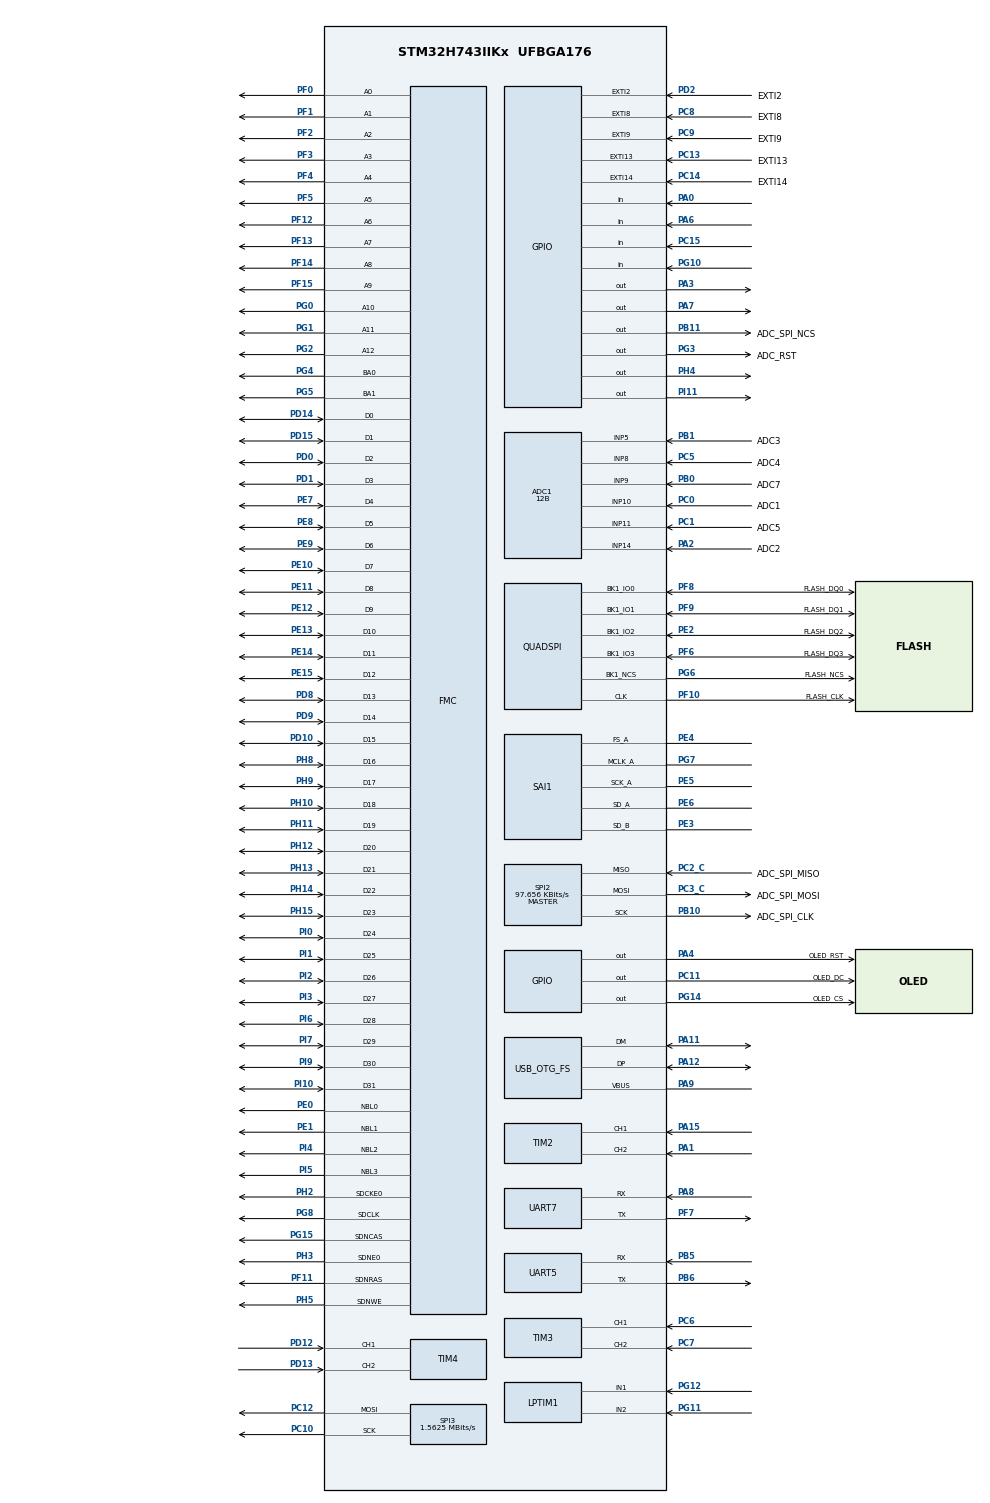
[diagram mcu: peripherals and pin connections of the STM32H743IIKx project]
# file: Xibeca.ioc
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Dma.SPI3_TX.2.MemInc=DMA_MINC_ENABLE
SH.FMC_A0.0=FMC_A0,13b-sda1
PG8.Signal=FMC_SDCLK
PG0.Signal=FMC_A10
RCC.PLLFRACN=0
PC3_C.Mode=Full_Duplex_Master
SAI1.Instance-SAI_A_MasterWithClock=SAI$Index_Block_A
PA15\ (JTDI).Signal=S_TIM2_CH1
SH.ADCx_INP5.0=ADC1_INP5,IN5-Single-Ended
SH.FMC_D5_DA5.0=FMC_D5,sd-32b-d1
SH.FMC_D9_DA9.0=FMC_D9,sd-32b-d1
USB_DEVICE.PID_AUDIO_FS=0xDADA
SH.FMC_D25.0=FMC_D25,sd-32b-d1
SAI1.FSDefinition-SAI_B_SyncSlave=SAI_FS_CHANNEL_IDENTIFICATION
PF7.Signal=UART7_TX
SH.FMC_SDNWE.0=FMC_SDNWE,13b-sda1
PH9.Signal=FMC_D17
SH.FMC_D11_DA11.0=FMC_D11,sd-32b-d1
Dma.SPI3_TX.2.PeriphDataAlignment=DMA_PDATAALIGN_BYTE
PB6.Signal=UART5_TX
PC7.Signal=S_TIM3_CH2
PD0.Signal=FMC_D2_DA2
SAI1.AudioMode-SAI_A_MasterWithClock=SAI_MODEMASTER_RX
PD8.Signal=FMC_D13_DA13
PE1.Signal=FMC_NBL1
QUADSPI.FlashSize=22
NVIC.EXTI15_10_IRQn=true\:5\:0\:false\:false\:true\:true\:true\:true
Dma.ADC1.3.RequestNumber=1
ADC1.OffsetSignedSaturation-3\#ChannelRegularConversion=DISABLE
USB_DEVICE.MANUFACTURER_STRING-AUDIO_FS=Rebel Technology
PC2_C.GPIO_Speed=GPIO_SPEED_FREQ_VERY_HIGH
RCC.SAI1CLockSelection=RCC_SAI1CLKSOURCE_PLL3
PE9.Signal=FMC_D6_DA6
Dma.SAI1_A.0.Polarity=HAL_DMAMUX_REQ_GEN_RISING
Dma.ADC1.3.Mode=DMA_CIRCULAR
SH.FMC_A2.0=FMC_A2,13b-sda1
PB1.GPIO_Label=ADC3
PA8.Signal=UART7_RX
SH.FMC_D1_DA1.0=FMC_D1,sd-32b-d1
Dma.SPI3_TX.2.Direction=DMA_MEMORY_TO_PERIPH
VP_FREERTOS_VS_CMSIS_V1.Mode=CMSIS_V1
PA0.Signal=GPIO_Input
Mcu.Package=UFBGA176
SAI1.AudioFrequency-SAI_A_MasterWithClock=SAI_AUDIO_FREQUENCY_48K
PB1.Signal=ADCx_INP5
PC10.Stacked=true
SAI1.SlotActive-SAI_B_SyncSlave=0x0000FFFF
SPI2.Mode=SPI_MODE_MASTER
ADC1.OversamplingMode=DISABLE
RCC.PLL3FRACN=0
SPI3.Mode=SPI_MODE_MASTER
PD12.Signal=S_TIM4_CH1
SAI1.FSPolarity-SAI_B_SyncSlave=SAI_FS_ACTIVE_HIGH
PC3_C.GPIO_Speed=GPIO_SPEED_FREQ_VERY_HIGH
PC3_C.GPIO_Label=ADC_SPI_MOSI
SH.FMC_D27.0=FMC_D27,sd-32b-d1
Dma.SAI1_A.0.SyncSignalID=NONE
NVIC.EXTI2_IRQn=true\:5\:0\:false\:false\:true\:true\:true\:true
SH.S_TIM4_CH1.0=TIM4_CH1,Encoder_Interface
PF10.Mode=Single Bank 1
PA4.GPIO_Label=OLED_RST
ADC1.EOCSelection=ADC_EOC_SEQ_CONV
PD15.Signal=FMC_D1_DA1
PG12.Signal=LPTIM1_IN1
SAI1.NoDivider-SAI_A_MasterWithClock=SAI_MASTERDIVIDER_ENABLE
USB_DEVICE.VID-AUDIO_FS=0x1209
SH.FMC_A4.0=FMC_A4,13b-sda1
FREERTOS.Tasks01=defaultTask,0,1024,StartDefaultTask,Default,NULL,Dynamic,NULL,NULL
PH13.Signal=FMC_D21
USB_DEVICE.VirtualMode-AUDIO_FS=Audio
Dma.SAI1_B.1.MemInc=DMA_MINC_ENABLE
SAI1.MClockEnable-SAI_A_MasterWithClock=SAI_MASTERCLOCK_ENABLE
PG5.Signal=FMC_A15_BA1
ADC1.OffsetNumber-0\#ChannelRegularConversion=ADC_OFFSET_NONE
PC13.Signal=GPXTI13
SH.FMC_D10_DA10.0=FMC_D10,sd-32b-d1
FREERTOS.INCLUDE_vTaskDelayUntil=1
Dma.ADC1.3.Priority=DMA_PRIORITY_LOW
SAI1.ErrorAudioFreq-SAI_A_MasterWithClock=-0.01 %
SH.FMC_D16.0=FMC_D16,sd-32b-d1
SH.ADCx_INP9.0=ADC1_INP9,IN9-Single-Ended
RCC.PWR_Regulator_Voltage_Scale=PWR_REGULATOR_VOLTAGE_SCALE0
PF8.GPIO_Label=FLASH_DQ0
PD10.Signal=FMC_D15_DA15
SH.FMC_D29.0=FMC_D29,sd-32b-d1
SAI1.VirtualMode-SAI_A_MasterWithClock=VM_MASTER
PI7.Signal=FMC_D29
PC2_C.GPIO_Label=ADC_SPI_MISO
SH.FMC_A6.0=FMC_A6,13b-sda1
PE14.Signal=FMC_D11_DA11
PE6.Mode=SAI_A_MasterWithClock
SAI1.SlotNumber-SAI_B_SyncSlave=8
Dma.ADC1.3.SyncSignalID=NONE
PI2.Signal=FMC_D26
Dma.ADC1.3.Polarity=HAL_DMAMUX_REQ_GEN_RISING
Dma.SAI1_A.0.SyncRequestNumber=1
FREERTOS.configUSE_MUTEXES=0
QUADSPI.FifoThreshold=4
PF13.Signal=FMC_A7
SH.SharedStack_PC8.0=SDMMC1_D0
SH.SharedStack_PC8.1=GPIO_EXTI8
SH.FMC_NBL2.0=FMC_NBL2,Sd4ByteEnable1
SH.FMC_D18.0=FMC_D18,sd-32b-d1
Dma.SPI3_TX.2.SyncEnable=DISABLE
ADC1.master=1
PC14-OSC32_IN\ (OSC32_IN).GPIO_Label=EXTI14
ProjectManager.HeapSize=0x200
NVIC.PriorityGroup=NVIC_PRIORITYGROUP_4
ADC1.ConversionDataManagement=ADC_CONVERSIONDATA_DMA_CIRCULAR
PE3.Signal=SAI1_SD_B
PF4.Signal=FMC_A4
PD2.Signal=SharedStack_PD2
Mcu.Family=STM32H7
SH.SharedStack_PC12.1=SPI3_MOSI,TX_Only_Simplex_Unidirect_Master
SH.SharedStack_PC12.0=SDMMC1_CK
USB_DEVICE.CLASS_NAME_FS=AUDIO
ADC1.OffsetSignedSaturation-1\#ChannelRegularConversion=DISABLE
SH.FMC_A8.0=FMC_A8,13b-sda1
PH14.Signal=FMC_D22
PH10.Signal=FMC_D18
ADC1.Overrun=ADC_OVR_DATA_OVERWRITTEN
ADC1.ContinuousConvMode=ENABLE
SH.FMC_D14_DA14.0=FMC_D14,sd-32b-d1
PH0-OSC_IN\ (PH0).Signal=RCC_OSC_IN
PG2.Signal=FMC_A12
SAI1.FrameLength-SAI_B_SyncSlave=256
TIM4.EncoderMode=TIM_ENCODERMODE_TI12
SAI1.FSDefinition-SAI_A_MasterWithClock=SAI_FS_CHANNEL_IDENTIFICATION
PE2.GPIO_Speed=GPIO_SPEED_FREQ_VERY_HIGH
PA11.Mode=Device_Only
PF9.GPIO_Speed=GPIO_SPEED_FREQ_VERY_HIGH
RCC.PLL2FRACN=6144
SAI1.OutputDrive-SAI_B_SyncSlave=SAI_OUTPUTDRIVE_ENABLE
SH.FMC_A14_BA0.0=FMC_BA0,FourSdramBanks1
SH.FMC_A11.0=FMC_A11,13b-sda1
Dma.SPI3_TX.2.Mode=DMA_NORMAL
PG15.Signal=FMC_SDNCAS
PG11.Signal=LPTIM1_IN2
PD13.Signal=S_TIM4_CH2
Dma.SPI3_TX.2.SignalID=NONE
SAI1.VirtualMode-SAI_B_SyncSlave=VM_SLAVE
Dma.SAI1_B.1.SyncPolarity=HAL_DMAMUX_SYNC_NO_EVENT
ADC1.Channel-3\#ChannelRegularConversion=ADC_CHANNEL_8
SAI1.ActiveFrameLength-SAI_B_SyncSlave=128
Dma.ADC1.3.SyncPolarity=HAL_DMAMUX_SYNC_NO_EVENT
ADC1.Resolution=ADC_RESOLUTION_12B
SH.FMC_NBL1.0=FMC_NBL1,Sd4ByteEnable1
Dma.SAI1_B.1.Instance=DMA1_Stream1
Dma.SAI1_B.1.FIFOMode=DMA_FIFOMODE_DISABLE
FREERTOS.configUSE_PREEMPTION=0
ADC1.Channel-0\#ChannelRegularConversion=ADC_CHANNEL_10
PH1-OSC_OUT\ (PH1).Mode=HSE-External-Oscillator
RCC.HSE_VALUE=8000000
SH.SharedStack_PC10.1=SPI3_SCK,TX_Only_Simplex_Unidirect_Master
PA4.GPIO_Speed=GPIO_SPEED_FREQ_MEDIUM
SH.SharedStack_PC10.0=SDMMC1_D2
PF9.Mode=Single Bank 1
PF11.Signal=FMC_SDNRAS
PC11.GPIO_Label=OLED_DC
PB5.Mode=Asynchronous
PB7.Signal=I2C1_SDA
SH.S_TIM3_CH1.0=TIM3_CH1,Encoder_Interface
SAI1.OutputDrive-SAI_A_MasterWithClock=SAI_OUTPUTDRIVE_ENABLE
USB_DEVICE.PRODUCT_STRING_AUDIO_FS=OWL-XIBECA
PA6.Signal=GPIO_Input
Dma.SAI1_A.0.MemDataAlignment=DMA_MDATAALIGN_WORD
NVIC.OTG_FS_IRQn=true\:5\:0\:false\:false\:true\:true\:true\:true
SAI1.FSOffset-SAI_A_MasterWithClock=SAI_FS_BEFOREFIRSTBIT
PF8.Signal=QUADSPI_BK1_IO0
NVIC.SPI3_IRQn=true\:5\:0\:false\:false\:true\:true\:false\:true
Dma.Request2=SPI3_TX
Dma.Request1=SAI1_B
Dma.SAI1_B.1.PeriphInc=DMA_PINC_DISABLE
Dma.Request3=ADC1
FREERTOS.configUSE_TICK_HOOK=0
NVIC.DMA1_Stream0_IRQn=true\:5\:0\:false\:false\:true\:true\:false\:true
PC5.Signal=ADCx_INP8
PH2.Mode=SdramChipSelect1_1
PE7.Signal=FMC_D4_DA4
Dma.Request0=SAI1_A
Dma.SAI1_B.1.Priority=DMA_PRIORITY_VERY_HIGH
PE2.GPIO_Label=FLASH_DQ2
PA3.Signal=GPIO_Output
SAI1.VirtualSlotActive-SAI_A_MasterWithClock=SAI_SLOTACTIVE_ALL
SH.FMC_D20.0=FMC_D20,sd-32b-d1
SH.S_TIM2_CH1.0=TIM2_CH1,Encoder_Interface
Dma.SAI1_B.1.Mode=DMA_CIRCULAR
PG7.Signal=SAI1_MCLK_A
PC9.GPIO_Label=EXTI9
Dma.SAI1_B.1.RequestNumber=1
Dma.SPI3_TX.2.Polarity=HAL_DMAMUX_REQ_GEN_RISING
Dma.SAI1_A.0.Direction=DMA_PERIPH_TO_MEMORY
PC11.Signal=GPIO_Output
Dma.SAI1_A.0.SignalID=NONE
SPI2.NSSPMode=SPI_NSS_PULSE_DISABLE
PC8.Signal=SharedStack_PC8
PF10.GPIO_Speed=GPIO_SPEED_FREQ_VERY_HIGH
SH.ADCx_INP14.0=ADC1_INP14,IN14-Single-Ended
SH.FMC_D31.0=FMC_D31,sd-32b-d1
PD9.Signal=FMC_D14_DA14
PC12.Stacked=true
PH1-OSC_OUT\ (PH1).Signal=RCC_OSC_OUT
FREERTOS.configUSE_IDLE_HOOK=0
SAI1.RealAudioFreq-SAI_A_MasterWithClock=47.991 KHz
PA9.Mode=Activate_VBUS
SH.SharedStack_PD2.0=SDMMC1_CMD
PF6.Signal=QUADSPI_BK1_IO3
SH.SharedStack_PD2.1=GPIO_EXTI2
PC15-OSC32_OUT\ (OSC32_OUT).Signal=GPIO_Input
PB10.GPIO_Label=ADC_SPI_CLK
Dma.SAI1_A.0.Mode=DMA_CIRCULAR
SH.FMC_D13_DA13.0=FMC_D13,sd-32b-d1
PH8.Signal=FMC_D16
Dma.ADC1.3.SyncRequestNumber=1
RCC.USBFreq_Value=48000000
PF9.GPIO_Label=FLASH_DQ1
Dma.SAI1_B.1.SyncEnable=DISABLE
PA1.Signal=S_TIM2_CH2
Dma.ADC1.3.Direction=DMA_PERIPH_TO_MEMORY
board=custom
PG12.Mode=Encoder_mode_occur1
PI9.Signal=FMC_D30
SH.FMC_D22.0=FMC_D22,sd-32b-d1
PI4.Signal=FMC_NBL2
PE5.Mode=SAI_A_MasterWithClock
RCC.ADCFreq_Value=25000000
PC1.GPIO_Label=ADC5
SH.FMC_D12_DA12.0=FMC_D12,sd-32b-d1
SAI1.SlotNumber-SAI_A_MasterWithClock=8
PF1.Signal=FMC_A1
VP_USB_DEVICE_VS_USB_DEVICE_AUDIO_FS.Mode=AUDIO_FS
ADC1.NbrOfConversion=4
ADC1.OffsetNumber-2\#ChannelRegularConversion=ADC_OFFSET_NONE
PE0.Signal=FMC_NBL0
Dma.SAI1_B.1.SyncSignalID=NONE
PE12.Signal=FMC_D9_DA9
RCC.SYSCLKFreq_VALUE=480000000
ADC1.Rank-3\#ChannelRegularConversion=4
ADC1.SamplingTime-3\#ChannelRegularConversion=ADC_SAMPLETIME_387CYCLES_5
NVIC.EXTI9_5_IRQn=true\:5\:0\:false\:false\:true\:true\:true\:true
PH3.Signal=FMC_SDNE0
PC3_C.Signal=SPI2_MOSI
PE5.GPIO_Speed=GPIO_SPEED_FREQ_VERY_HIGH
NVIC.DMA1_Stream3_IRQn=true\:5\:0\:false\:false\:true\:true\:false\:true
PG14.GPIO_Speed=GPIO_SPEED_FREQ_MEDIUM
PC12.GPIO_Speed=GPIO_SPEED_FREQ_HIGH
Dma.SAI1_A.0.SyncEnable=DISABLE
SAI1.SlotActive-SAI_A_MasterWithClock=0x0000FFFF
SH.FMC_D7_DA7.0=FMC_D7,sd-32b-d1
SH.FMC_D24.0=FMC_D24,sd-32b-d1
SPI3.Direction=SPI_DIRECTION_2LINES_TXONLY
SPI3.VirtualType=VM_MASTER
PH12.Signal=FMC_D20
QUADSPI.ClockPrescaler=9
SPI2.VirtualType=VM_MASTER
PB10.Mode=Full_Duplex_Master
SH.ADCx_INP10.0=ADC1_INP10,IN10-Single-Ended
PG4.Signal=FMC_A14_BA0
NVIC.DMA1_Stream2_IRQn=true\:5\:0\:false\:false\:true\:true\:false\:true
PC12.Signal=SharedStack_PC12
PG6.GPIO_Label=FLASH_NCS
PG6.Mode=Single Bank 1
PF6.GPIO_Label=FLASH_DQ3
RCC.SYSCLKSource=RCC_SYSCLKSOURCE_PLLCLK
SH.FMC_A15_BA1.0=FMC_BA1,FourSdramBanks1
RCC.SPI123CLockSelection=RCC_SPI123CLKSOURCE_PLL2
Dma.ADC1.3.MemInc=DMA_MINC_ENABLE
PA14\ (JTCK/SWCLK).Signal=DEBUG_JTCK-SWCLK
PH5.Signal=FMC_SDNWE
Dma.SPI3_TX.2.SyncRequestNumber=1
PE2.Mode=Single Bank 1
ADC1.Channel-2\#ChannelRegularConversion=ADC_CHANNEL_5
PB6.Mode=Asynchronous
PE5.Signal=SAI1_SCK_A
PF10.GPIO_Label=FLASH_CLK
Dma.SAI1_B.1.PeriphDataAlignment=DMA_PDATAALIGN_WORD
RCC.DIVM3=7
RCC.DIVM2=1
RCC.DIVM1=1
Dma.ADC1.3.Instance=DMA1_Stream3
SH.FMC_D26.0=FMC_D26,sd-32b-d1
PI6.Signal=FMC_D28
PI3.Signal=FMC_D27
SPI2.CalculateBaudRate=97.656 KBits/s
PC11.GPIO_Speed=GPIO_SPEED_FREQ_MEDIUM
SH.S_TIM4_CH2.0=TIM4_CH2,Encoder_Interface
PE2.Signal=QUADSPI_BK1_IO2
PF8.Mode=Single Bank 1
PA14\ (JTCK/SWCLK).Mode=Trace_Asynchronous_SW
PF3.Signal=FMC_A3
NVIC.SAI1_IRQn=true\:5\:0\:false\:false\:true\:true\:true\:true
PE10.Signal=FMC_D7_DA7
ADC1.SamplingTime-0\#ChannelRegularConversion=ADC_SAMPLETIME_387CYCLES_5
SH.FMC_A1.0=FMC_A1,13b-sda1
PH2.Signal=FMC_SDCKE0
SH.FMC_SDCLK.0=FMC_SDCLK,13b-sda1
RCC.APB4Freq_Value=120000000
PF14.Signal=FMC_A8
SAI1.FrameLength-SAI_A_MasterWithClock=256
PI11.Signal=GPIO_Output
PH0-OSC_IN\ (PH0).Mode=HSE-External-Oscillator
PE6.GPIO_Speed=GPIO_SPEED_FREQ_VERY_HIGH
SH.FMC_D3_DA3.0=FMC_D3,sd-32b-d1
PG6.GPIO_Speed=GPIO_SPEED_FREQ_VERY_HIGH
Dma.SAI1_B.1.EventEnable=DISABLE
NVIC.QUADSPI_IRQn=true\:5\:0\:false\:false\:true\:true\:true\:true
PH15.Signal=FMC_D23
SAI1.DataSize-SAI_B_SyncSlave=SAI_DATASIZE_24
RCC.DIVQ1=5
ADC1.Rank-0\#ChannelRegularConversion=1
SH.FMC_D28.0=FMC_D28,sd-32b-d1
FREERTOS.configCHECK_FOR_STACK_OVERFLOW=2
Dma.SPI3_TX.2.EventEnable=DISABLE
PC6.Signal=S_TIM3_CH1
PB11.GPIO_Label=ADC_SPI_NCS
PD1.Signal=FMC_D3_DA3
RCC.DIVP2=6
TIM4.IC2Filter=4
PC0.Signal=ADCx_INP10
PC9.Stacked=true
PG10.Signal=GPIO_Input
SH.FMC_A3.0=FMC_A3,13b-sda1
Dma.SAI1_A.0.RequestNumber=1
SH.FMC_D15_DA15.0=FMC_D15,sd-32b-d1
PA9.Signal=USB_OTG_FS_VBUS
RCC.DIVN3=172
RCC.DIVN2=18
RCC.DIVN1=120
PC2_C.Mode=Full_Duplex_Master
SH.SharedStack_PC9.0=SDMMC1_D1
SH.SharedStack_PC9.1=GPIO_EXTI9
SH.FMC_D17.0=FMC_D17,sd-32b-d1
ADC1.OffsetSignedSaturation-0\#ChannelRegularConversion=DISABLE
SH.ADCx_INP8.0=ADC1_INP8,IN8-Single-Ended
PB10.Signal=SPI2_SCK
RCC.USBCLockSelection=RCC_USBCLKSOURCE_HSI48
Dma.SAI1_A.0.PeriphInc=DMA_PINC_DISABLE
PE15.Signal=FMC_D12_DA12
PE8.Signal=FMC_D5_DA5
PI1.Signal=FMC_D25
SH.FMC_SDNCAS.0=FMC_SDNCAS,13b-sda1
PG14.GPIO_Label=OLED_CS
Dma.SAI1_B.1.MemDataAlignment=DMA_MDATAALIGN_WORD
PA4.Signal=GPIO_Output
ADC1.SamplingTime-1\#ChannelRegularConversion=ADC_SAMPLETIME_387CYCLES_5
PB5.Signal=UART5_RX
PE3.GPIO_Speed=GPIO_SPEED_FREQ_VERY_HIGH
ADC1.Rank-1\#ChannelRegularConversion=2
SH.FMC_A5.0=FMC_A5,13b-sda1
PG11.Mode=Encoder_mode_occur1
PA11.Signal=USB_OTG_FS_DM
Dma.SPI3_TX.2.PeriphInc=DMA_PINC_DISABLE
Dma.ADC1.3.SignalID=NONE
PF6.Mode=Single Bank 1
PF9.Signal=QUADSPI_BK1_IO1
PB3\ (JTDO/TRACESWO).Mode=Trace_Asynchronous_SW
Dma.ADC1.3.EventEnable=DISABLE
PA8.Mode=Asynchronous
SPI2.DataSize=SPI_DATASIZE_8BIT
SH.FMC_NBL3.0=FMC_NBL3,Sd4ByteEnable1
PG3.GPIO_Label=ADC_RST
PB0.Signal=ADCx_INP9
SAI1.SlotSize-SAI_B_SyncSlave=SAI_SLOTSIZE_32B
SH.FMC_D19.0=FMC_D19,sd-32b-d1
Dma.SAI1_A.0.FIFOMode=DMA_FIFOMODE_DISABLE
PC1.Signal=ADCx_INP11
Dma.SAI1_A.0.Instance=DMA1_Stream0
PD2.GPIO_Label=EXTI2
Dma.SAI1_A.0.PeriphDataAlignment=DMA_PDATAALIGN_WORD
PA13\ (JTMS/SWDIO).Signal=DEBUG_JTMS-SWDIO
PF6.GPIO_Speed=GPIO_SPEED_FREQ_VERY_HIGH
RCC.CortexFreq_Value=480000000
PG6.Signal=QUADSPI_BK1_NCS
PB10.GPIO_Speed=GPIO_SPEED_FREQ_VERY_HIGH
Dma.SPI3_TX.2.Instance=DMA1_Stream2
RCC.HPRE=RCC_HCLK_DIV2
SPI3.NSSPMode=SPI_NSS_PULSE_DISABLE
PC10.Signal=SharedStack_PC10
SH.FMC_NBL0.0=FMC_NBL0,Sd4ByteEnable1
PC0.GPIO_Label=ADC1
SH.FMC_D6_DA6.0=FMC_D6,sd-32b-d1
PB0.GPIO_Label=ADC7
PC10.GPIO_Speed=GPIO_SPEED_FREQ_HIGH
PC13.GPIO_Label=EXTI13
Dma.ADC1.3.PeriphDataAlignment=DMA_PDATAALIGN_HALFWORD
PB11.Signal=GPIO_Output
SAI1.ActiveFrameLength-SAI_A_MasterWithClock=128
Dma.SPI3_TX.2.SyncSignalID=NONE
ProjectManager.StackSize=0x400
PH3.Mode=SdramChipSelect1_1
NVIC.ADC_IRQn=true\:5\:0\:false\:false\:true\:true\:true\:true
SH.FMC_A7.0=FMC_A7,13b-sda1
PA12.Signal=USB_OTG_FS_DP
SPI2.CLKPolarity=SPI_POLARITY_HIGH
RCC.HCLKFreq_Value=240000000
Dma.ADC1.3.PeriphInc=DMA_PINC_DISABLE
PF12.Signal=FMC_A6
FREERTOS.configUSE_MALLOC_FAILED_HOOK=1
Dma.SAI1_A.0.SyncPolarity=HAL_DMAMUX_SYNC_NO_EVENT
PC2_C.Signal=SPI2_MISO
SH.FMC_A10.0=FMC_A10,13b-sda1
SPI2.BaudRatePrescaler=SPI_BAUDRATEPRESCALER_256
SPI3.DataSize=SPI_DATASIZE_8BIT
SH.FMC_D8_DA8.0=FMC_D8,sd-32b-d1
PC8.Stacked=true
SH.FMC_D2_DA2.0=FMC_D2,sd-32b-d1
ADC1.Rank-2\#ChannelRegularConversion=3
PE13.Signal=FMC_D10_DA10
PI5.Signal=FMC_NBL3
PE4.GPIO_Speed=GPIO_SPEED_FREQ_VERY_HIGH
PI0.Signal=FMC_D24
Dma.SAI1_A.0.EventEnable=DISABLE
PE4.Mode=SAI_A_MasterWithClock
Dma.SPI3_TX.2.Priority=DMA_PRIORITY_LOW
SH.FMC_SDNRAS.0=FMC_SDNRAS,13b-sda1
PE4.Signal=SAI1_FS_A
RCC.APB3Freq_Value=120000000
SAI1.VirtualSlotActive-SAI_B_SyncSlave=SAI_SLOTACTIVE_ALL
Dma.SPI3_TX.2.FIFOMode=DMA_FIFOMODE_DISABLE
SH.FMC_D0_DA0.0=FMC_D0,sd-32b-d1
RCC.D1PPRE=RCC_APB3_DIV2
PA2.GPIO_Label=ADC2
USB_OTG_FS.VirtualMode=Device_Only
SH.FMC_A9.0=FMC_A9,13b-sda1
ADC1.OffsetNumber-1\#ChannelRegularConversion=ADC_OFFSET_NONE
SH.FMC_D4_DA4.0=FMC_D4,sd-32b-d1
SPI2.CLKPhase=SPI_PHASE_2EDGE
TIM4.IC1Filter=4
PF5.Signal=FMC_A5
Dma.SAI1_B.1.SignalID=NONE
Dma.SPI3_TX.2.RequestNumber=1
SH.FMC_D30.0=FMC_D30,sd-32b-d1
SPI2.Direction=SPI_DIRECTION_2LINES
PF0.Signal=FMC_A0
PE3.Mode=SAI_B_SyncSlave
SH.FMC_A12.0=FMC_A12,13b-sda1
RCC.PLLSourceVirtual=RCC_PLLSOURCE_HSE
PA13\ (JTMS/SWDIO).Mode=Trace_Asynchronous_SW
Dma.SAI1_B.1.Polarity=HAL_DMAMUX_REQ_GEN_RISING
PH11.Signal=FMC_D19
USB_DEVICE.VirtualModeFS=Audio_FS
PG3.Signal=GPIO_Output
PG1.Signal=FMC_A11
SAI1.FSPolarity-SAI_A_MasterWithClock=SAI_FS_ACTIVE_HIGH
ADC1.OffsetNumber-3\#ChannelRegularConversion=ADC_OFFSET_NONE
RCC.D2PPRE2=RCC_APB2_DIV2
RCC.D2PPRE1=RCC_APB1_DIV2
PI10.Signal=FMC_D31
NVIC.DMA1_Stream1_IRQn=true\:5\:0\:false\:false\:true\:true\:false\:true
Dma.SAI1_A.0.MemInc=DMA_MINC_ENABLE
Dma.SPI3_TX.2.SyncPolarity=HAL_DMAMUX_SYNC_NO_EVENT
Dma.ADC1.3.FIFOMode=DMA_FIFOMODE_DISABLE
ADC1.SamplingTime-2\#ChannelRegularConversion=ADC_SAMPLETIME_387CYCLES_5
PD2.Stacked=true
Dma.ADC1.3.SyncEnable=DISABLE
PC8.GPIO_Label=EXTI8
SH.FMC_D21.0=FMC_D21,sd-32b-d1
PF7.Mode=Asynchronous
SH.S_TIM2_CH2.0=TIM2_CH2,Encoder_Interface
PH4.Signal=GPIO_Output
PB3\ (JTDO/TRACESWO).Signal=DEBUG_JTDO-SWO
ProjectManager.TargetToolchain=Other Toolchains (GPDSC)
SAI1.SlotSize-SAI_A_MasterWithClock=SAI_SLOTSIZE_32B
ADC1.OffsetSignedSaturation-2\#ChannelRegularConversion=DISABLE
ADC1.Channel-1\#ChannelRegularConversion=ADC_CHANNEL_14
SAI1.DataSize-SAI_A_MasterWithClock=SAI_DATASIZE_24
PF2.Signal=FMC_A2
PG7.Mode=SAI_A_MasterWithClock
PE11.Signal=FMC_D8_DA8
SAI1.AudioMode-SAI_B_SyncSlave=SAI_MODESLAVE_TX
Dma.SAI1_A.0.Priority=DMA_PRIORITY_VERY_HIGH
PG14.Signal=GPIO_Output
SH.S_TIM3_CH2.0=TIM3_CH2,Encoder_Interface
Dma.ADC1.3.MemDataAlignment=DMA_MDATAALIGN_HALFWORD
PG7.GPIO_Speed=GPIO_SPEED_FREQ_VERY_HIGH
RCC.APB2Freq_Value=120000000
SPI3.CalculateBaudRate=1.5625 MBits/s
PF10.Signal=QUADSPI_CLK
Dma.SPI3_TX.2.MemDataAlignment=DMA_MDATAALIGN_BYTE
SPI3.BaudRatePrescaler=SPI_BAUDRATEPRESCALER_16
PD13.GPIO_PuPd=GPIO_PULLUP
PF15.Signal=FMC_A9
PE6.Signal=SAI1_SD_A
Mcu.Name=STM32H743IIKx
PA2.Signal=ADCx_INP14
PD14.Signal=FMC_D0_DA0
PA12.Mode=Device_Only
Dma.SAI1_B.1.Direction=DMA_MEMORY_TO_PERIPH
PC14-OSC32_IN\ (OSC32_IN).Signal=GPXTI14
PC5.GPIO_Label=ADC4
SH.FMC_D23.0=FMC_D23,sd-32b-d1
SAI1.Instance-SAI_B_SyncSlave=SAI$Index_Block_B
SH.ADCx_INP11.0=ADC1_INP11,IN11-Single-Ended
ADC1.NbrOfConversionFlag=1
SAI1.FSOffset-SAI_B_SyncSlave=SAI_FS_BEFOREFIRSTBIT
PF8.GPIO_Speed=GPIO_SPEED_FREQ_VERY_HIGH
Dma.SAI1_B.1.SyncRequestNumber=1
RCC.D3PPRE=RCC_APB4_DIV2
PC9.Signal=SharedStack_PC9
NVIC.TIM4_IRQn=true\:5\:0\:false\:false\:true\:true\:true\:true
RCC.APB1Freq_Value=120000000
ADC1.ClockPrescaler=ADC_CLOCK_SYNC_PCLK_DIV4
SAI1.ClockStrobing-SAI_A_MasterWithClock=SAI_CLOCKSTROBING_RISINGEDGE
PD12.GPIO_PuPd=GPIO_PULLUP
PA7.Signal=GPIO_Output

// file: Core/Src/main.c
/* USER CODE BEGIN Header */
/**
  ******************************************************************************
  * @file           : main.c
  * @brief          : Main program body
  ******************************************************************************
  * @attention
  *
  * <h2><center>&copy; Copyright (c) 2021 STMicroelectronics.
  * All rights reserved.</center></h2>
  *
  * This software component is licensed by ST under Ultimate Liberty license
  * SLA0044, the "License"; You may not use this file except in compliance with
  * the License. You may obtain a copy of the License at:
  *                             www.st.com/SLA0044
  *
  ******************************************************************************
  */
/* USER CODE END Header */
#include "main.h"
#include "cmsis_os.h"
#include "usb_device.h"

/* USER CODE BEGIN Includes */
#include "device.h"
#include "errorhandlers.h"
/* USER CODE END Includes */

ADC_HandleTypeDef hadc1;
DMA_HandleTypeDef hdma_adc1;

LPTIM_HandleTypeDef hlptim1;

QSPI_HandleTypeDef hqspi;

SAI_HandleTypeDef hsai_BlockA1;
SAI_HandleTypeDef hsai_BlockB1;
DMA_HandleTypeDef hdma_sai1_a;
DMA_HandleTypeDef hdma_sai1_b;

SPI_HandleTypeDef hspi2;
SPI_HandleTypeDef hspi3;
DMA_HandleTypeDef hdma_spi3_tx;

TIM_HandleTypeDef htim2;
TIM_HandleTypeDef htim3;
TIM_HandleTypeDef htim4;

UART_HandleTypeDef huart5;
UART_HandleTypeDef huart7;

SDRAM_HandleTypeDef hsdram1;

osThreadId defaultTaskHandle;

void SystemClock_Config(void);
void PeriphCommonClock_Config(void);
static void MX_GPIO_Init(void);
static void MX_DMA_Init(void);
static void MX_QUADSPI_Init(void);
static void MX_FMC_Init(void);
static void MX_SAI1_Init(void);
static void MX_ADC1_Init(void);
static void MX_SPI2_Init(void);
static void MX_SPI3_Init(void);
static void MX_TIM2_Init(void);
static void MX_TIM3_Init(void);
static void MX_TIM4_Init(void);
static void MX_UART5_Init(void);
static void MX_UART7_Init(void);
static void MX_LPTIM1_Init(void);
void StartDefaultTask(void const * argument);

/* USER CODE BEGIN PFP */
void setup(void);
void loop(void);
void SDRAM_Initialization_Sequence(SDRAM_HandleTypeDef *hsdram);
void initialise_monitor_handles(void);
/* USER CODE END PFP */

int main(void)
{
  /* USER CODE BEGIN 1 */
#ifdef DEBUG
#warning "DEBUG uses printf and semihosting!"
  if(CoreDebug->DHCSR & 0x01)
    initialise_monitor_handles(); // remove when not semi-hosting
  printf("showtime\n");
#endif
#ifdef USE_ICACHE
  /* Enable I-Cache-------------------------------------------------------------*/
  /* After reset, you must invalidate each cache before enabling (SCB_EnableICache) it. */
  SCB_InvalidateICache();
  SCB_EnableICache();
#endif
#ifdef USE_DCACHE
  /* Enable D-Cache-------------------------------------------------------------*/
  /* Before enabling the data cache, you must invalidate the entire data cache (SCB_InvalidateDCache), because external memory might have changed from when the cache was disabled. */
  SCB_InvalidateDCache();
  SCB_EnableDCache();
#endif

  /* Enable D2 domain SRAM Clocks */
  /* presumably done in SystemInit by setting DATA_IN_D2_SRAM ? */
  /* should be started before libc_init_array and LoopCopyData in startup.s */
  /* __HAL_RCC_D2SRAM1_CLK_ENABLE(); */
  /* __HAL_RCC_D2SRAM2_CLK_ENABLE(); */
  /* __HAL_RCC_D2SRAM3_CLK_ENABLE(); */

  /* USER CODE END 1 */

  /* MCU Configuration--------------------------------------------------------*/

  /* Reset of all peripherals, Initializes the Flash interface and the Systick. */
  HAL_Init();

  /* Configure the system clock */
  SystemClock_Config();

/* Configure the peripherals common clocks */
  PeriphCommonClock_Config();

  /* Initialize all configured peripherals */
  MX_GPIO_Init();
  MX_DMA_Init();
  MX_QUADSPI_Init();
  MX_FMC_Init();
  MX_SAI1_Init();
  MX_ADC1_Init();
  MX_SPI2_Init();
  MX_SPI3_Init();
  MX_TIM2_Init();
  MX_TIM3_Init();
  MX_TIM4_Init();
  MX_UART5_Init();
  MX_UART7_Init();
  MX_LPTIM1_Init();
  /* USER CODE BEGIN 2 */

#ifdef USE_EXTERNAL_RAM
  SDRAM_Initialization_Sequence(&hsdram1);
#endif

  /* USER CODE END 2 */

  /* Create the thread(s) */
  /* definition and creation of defaultTask */
  osThreadDef(defaultTask, StartDefaultTask, osPriorityNormal, 0, 1024);
  defaultTaskHandle = osThreadCreate(osThread(defaultTask), NULL);

  /* Start scheduler */
  osKernelStart();

  /* We should never get here as control is now taken by the scheduler */
  /* Infinite loop */
  while (1)
  {

  }
}

void SystemClock_Config(void)
{
  RCC_OscInitTypeDef RCC_OscInitStruct = {0};
  RCC_ClkInitTypeDef RCC_ClkInitStruct = {0};

  /** Supply configuration update enable
  */
  HAL_PWREx_ConfigSupply(PWR_LDO_SUPPLY);
  /** Configure the main internal regulator output voltage
  */
  __HAL_PWR_VOLTAGESCALING_CONFIG(PWR_REGULATOR_VOLTAGE_SCALE0);

  while(!__HAL_PWR_GET_FLAG(PWR_FLAG_VOSRDY)) {}
  /** Macro to configure the PLL clock source
  */
  __HAL_RCC_PLL_PLLSOURCE_CONFIG(RCC_PLLSOURCE_HSE);
  /** Initializes the RCC Oscillators according to the specified parameters
  * in the RCC_OscInitTypeDef structure.
  */
  RCC_OscInitStruct.OscillatorType = RCC_OSCILLATORTYPE_HSI48|RCC_OSCILLATORTYPE_HSE;
  RCC_OscInitStruct.HSEState = RCC_HSE_ON;
  RCC_OscInitStruct.HSI48State = RCC_HSI48_ON;
  RCC_OscInitStruct.PLL.PLLState = RCC_PLL_ON;
  RCC_OscInitStruct.PLL.PLLSource = RCC_PLLSOURCE_HSE;
  RCC_OscInitStruct.PLL.PLLM = 1;
  RCC_OscInitStruct.PLL.PLLN = 120;
  RCC_OscInitStruct.PLL.PLLP = 2;
  RCC_OscInitStruct.PLL.PLLQ = 5;
  RCC_OscInitStruct.PLL.PLLR = 2;
  RCC_OscInitStruct.PLL.PLLRGE = RCC_PLL1VCIRANGE_3;
  RCC_OscInitStruct.PLL.PLLVCOSEL = RCC_PLL1VCOWIDE;
  RCC_OscInitStruct.PLL.PLLFRACN = 0;
  if (HAL_RCC_OscConfig(&RCC_OscInitStruct) != HAL_OK)
  {
    Error_Handler();
  }
  /** Initializes the CPU, AHB and APB buses clocks
  */
  RCC_ClkInitStruct.ClockType = RCC_CLOCKTYPE_HCLK|RCC_CLOCKTYPE_SYSCLK
                              |RCC_CLOCKTYPE_PCLK1|RCC_CLOCKTYPE_PCLK2
                              |RCC_CLOCKTYPE_D3PCLK1|RCC_CLOCKTYPE_D1PCLK1;
  RCC_ClkInitStruct.SYSCLKSource = RCC_SYSCLKSOURCE_PLLCLK;
  RCC_ClkInitStruct.SYSCLKDivider = RCC_SYSCLK_DIV1;
  RCC_ClkInitStruct.AHBCLKDivider = RCC_HCLK_DIV2;
  RCC_ClkInitStruct.APB3CLKDivider = RCC_APB3_DIV2;
  RCC_ClkInitStruct.APB1CLKDivider = RCC_APB1_DIV2;
  RCC_ClkInitStruct.APB2CLKDivider = RCC_APB2_DIV2;
  RCC_ClkInitStruct.APB4CLKDivider = RCC_APB4_DIV2;

  if (HAL_RCC_ClockConfig(&RCC_ClkInitStruct, FLASH_LATENCY_4) != HAL_OK)
  {
    Error_Handler();
  }
}

void PeriphCommonClock_Config(void)
{
  RCC_PeriphCLKInitTypeDef PeriphClkInitStruct = {0};

  /** Initializes the peripherals clock
  */
  PeriphClkInitStruct.PeriphClockSelection = RCC_PERIPHCLK_SAI1|RCC_PERIPHCLK_SPI3
                              |RCC_PERIPHCLK_SPI2;
  PeriphClkInitStruct.PLL2.PLL2M = 1;
  PeriphClkInitStruct.PLL2.PLL2N = 18;
  PeriphClkInitStruct.PLL2.PLL2P = 6;
  PeriphClkInitStruct.PLL2.PLL2Q = 2;
  PeriphClkInitStruct.PLL2.PLL2R = 2;
  PeriphClkInitStruct.PLL2.PLL2RGE = RCC_PLL2VCIRANGE_3;
  PeriphClkInitStruct.PLL2.PLL2VCOSEL = RCC_PLL2VCOMEDIUM;
  PeriphClkInitStruct.PLL2.PLL2FRACN = 6144;
  PeriphClkInitStruct.PLL3.PLL3M = 7;
  PeriphClkInitStruct.PLL3.PLL3N = 172;
  PeriphClkInitStruct.PLL3.PLL3P = 2;
  PeriphClkInitStruct.PLL3.PLL3Q = 2;
  PeriphClkInitStruct.PLL3.PLL3R = 2;
  PeriphClkInitStruct.PLL3.PLL3RGE = RCC_PLL3VCIRANGE_0;
  PeriphClkInitStruct.PLL3.PLL3VCOSEL = RCC_PLL3VCOWIDE;
  PeriphClkInitStruct.PLL3.PLL3FRACN = 0;
  PeriphClkInitStruct.Sai1ClockSelection = RCC_SAI1CLKSOURCE_PLL3;
  PeriphClkInitStruct.Spi123ClockSelection = RCC_SPI123CLKSOURCE_PLL2;
  if (HAL_RCCEx_PeriphCLKConfig(&PeriphClkInitStruct) != HAL_OK)
  {
    Error_Handler();
  }
}

static void MX_ADC1_Init(void)
{

  ADC_MultiModeTypeDef multimode = {0};
  ADC_ChannelConfTypeDef sConfig = {0};

  /** Common config
  */
  hadc1.Instance = ADC1;
  hadc1.Init.ClockPrescaler = ADC_CLOCK_SYNC_PCLK_DIV4;
  hadc1.Init.Resolution = ADC_RESOLUTION_12B;
  hadc1.Init.ScanConvMode = ADC_SCAN_ENABLE;
  hadc1.Init.EOCSelection = ADC_EOC_SEQ_CONV;
  hadc1.Init.LowPowerAutoWait = DISABLE;
  hadc1.Init.ContinuousConvMode = ENABLE;
  hadc1.Init.NbrOfConversion = 4;
  hadc1.Init.DiscontinuousConvMode = DISABLE;
  hadc1.Init.ExternalTrigConv = ADC_SOFTWARE_START;
  hadc1.Init.ExternalTrigConvEdge = ADC_EXTERNALTRIGCONVEDGE_NONE;
  hadc1.Init.ConversionDataManagement = ADC_CONVERSIONDATA_DMA_CIRCULAR;
  hadc1.Init.Overrun = ADC_OVR_DATA_OVERWRITTEN;
  hadc1.Init.LeftBitShift = ADC_LEFTBITSHIFT_NONE;
  hadc1.Init.OversamplingMode = DISABLE;
  if (HAL_ADC_Init(&hadc1) != HAL_OK)
  {
    Error_Handler();
  }
  /** Configure the ADC multi-mode
  */
  multimode.Mode = ADC_MODE_INDEPENDENT;
  if (HAL_ADCEx_MultiModeConfigChannel(&hadc1, &multimode) != HAL_OK)
  {
    Error_Handler();
  }
  /** Configure Regular Channel
  */
  sConfig.Channel = ADC_CHANNEL_10;
  sConfig.Rank = ADC_REGULAR_RANK_1;
  sConfig.SamplingTime = ADC_SAMPLETIME_387CYCLES_5;
  sConfig.SingleDiff = ADC_SINGLE_ENDED;
  sConfig.OffsetNumber = ADC_OFFSET_NONE;
  sConfig.Offset = 0;
  sConfig.OffsetSignedSaturation = DISABLE;
  if (HAL_ADC_ConfigChannel(&hadc1, &sConfig) != HAL_OK)
  {
    Error_Handler();
  }
  /** Configure Regular Channel
  */
  sConfig.Channel = ADC_CHANNEL_14;
  sConfig.Rank = ADC_REGULAR_RANK_2;
  if (HAL_ADC_ConfigChannel(&hadc1, &sConfig) != HAL_OK)
  {
    Error_Handler();
  }
  /** Configure Regular Channel
  */
  sConfig.Channel = ADC_CHANNEL_5;
  sConfig.Rank = ADC_REGULAR_RANK_3;
  if (HAL_ADC_ConfigChannel(&hadc1, &sConfig) != HAL_OK)
  {
    Error_Handler();
  }
  /** Configure Regular Channel
  */
  sConfig.Channel = ADC_CHANNEL_8;
  sConfig.Rank = ADC_REGULAR_RANK_4;
  if (HAL_ADC_ConfigChannel(&hadc1, &sConfig) != HAL_OK)
  {
    Error_Handler();
  }

}

static void MX_LPTIM1_Init(void)
{

  hlptim1.Instance = LPTIM1;
  hlptim1.Init.Clock.Source = LPTIM_CLOCKSOURCE_APBCLOCK_LPOSC;
  hlptim1.Init.Clock.Prescaler = LPTIM_PRESCALER_DIV1;
  hlptim1.Init.UltraLowPowerClock.Polarity = LPTIM_CLOCKPOLARITY_RISING;
  hlptim1.Init.UltraLowPowerClock.SampleTime = LPTIM_CLOCKSAMPLETIME_DIRECTTRANSITION;
  hlptim1.Init.Trigger.Source = LPTIM_TRIGSOURCE_SOFTWARE;
  hlptim1.Init.OutputPolarity = LPTIM_OUTPUTPOLARITY_HIGH;
  hlptim1.Init.UpdateMode = LPTIM_UPDATE_IMMEDIATE;
  hlptim1.Init.CounterSource = LPTIM_COUNTERSOURCE_EXTERNAL;
  hlptim1.Init.Input1Source = LPTIM_INPUT1SOURCE_GPIO;
  hlptim1.Init.Input2Source = LPTIM_INPUT2SOURCE_GPIO;
  if (HAL_LPTIM_Init(&hlptim1) != HAL_OK)
  {
    Error_Handler();
  }

}

static void MX_QUADSPI_Init(void)
{

  /* QUADSPI parameter configuration*/
  hqspi.Instance = QUADSPI;
  hqspi.Init.ClockPrescaler = 9;
  hqspi.Init.FifoThreshold = 4;
  hqspi.Init.SampleShifting = QSPI_SAMPLE_SHIFTING_NONE;
  hqspi.Init.FlashSize = 22;
  hqspi.Init.ChipSelectHighTime = QSPI_CS_HIGH_TIME_1_CYCLE;
  hqspi.Init.ClockMode = QSPI_CLOCK_MODE_0;
  hqspi.Init.FlashID = QSPI_FLASH_ID_1;
  hqspi.Init.DualFlash = QSPI_DUALFLASH_DISABLE;
  if (HAL_QSPI_Init(&hqspi) != HAL_OK)
  {
    Error_Handler();
  }

}

static void MX_SAI1_Init(void)
{

  hsai_BlockA1.Instance = SAI1_Block_A;
  hsai_BlockA1.Init.Protocol = SAI_FREE_PROTOCOL;
  hsai_BlockA1.Init.AudioMode = SAI_MODEMASTER_RX;
  hsai_BlockA1.Init.DataSize = SAI_DATASIZE_24;
  hsai_BlockA1.Init.FirstBit = SAI_FIRSTBIT_MSB;
  hsai_BlockA1.Init.ClockStrobing = SAI_CLOCKSTROBING_RISINGEDGE;
  hsai_BlockA1.Init.Synchro = SAI_ASYNCHRONOUS;
  hsai_BlockA1.Init.OutputDrive = SAI_OUTPUTDRIVE_ENABLE;
  hsai_BlockA1.Init.NoDivider = SAI_MASTERDIVIDER_ENABLE;
  hsai_BlockA1.Init.FIFOThreshold = SAI_FIFOTHRESHOLD_EMPTY;
  hsai_BlockA1.Init.AudioFrequency = SAI_AUDIO_FREQUENCY_48K;
  hsai_BlockA1.Init.SynchroExt = SAI_SYNCEXT_DISABLE;
  hsai_BlockA1.Init.MonoStereoMode = SAI_STEREOMODE;
  hsai_BlockA1.Init.CompandingMode = SAI_NOCOMPANDING;
  hsai_BlockA1.Init.PdmInit.Activation = DISABLE;
  hsai_BlockA1.Init.PdmInit.MicPairsNbr = 1;
  hsai_BlockA1.Init.PdmInit.ClockEnable = SAI_PDM_CLOCK1_ENABLE;
  hsai_BlockA1.FrameInit.FrameLength = 256;
  hsai_BlockA1.FrameInit.ActiveFrameLength = 128;
  hsai_BlockA1.FrameInit.FSDefinition = SAI_FS_CHANNEL_IDENTIFICATION;
  hsai_BlockA1.FrameInit.FSPolarity = SAI_FS_ACTIVE_HIGH;
  hsai_BlockA1.FrameInit.FSOffset = SAI_FS_BEFOREFIRSTBIT;
  hsai_BlockA1.SlotInit.FirstBitOffset = 0;
  hsai_BlockA1.SlotInit.SlotSize = SAI_SLOTSIZE_32B;
  hsai_BlockA1.SlotInit.SlotNumber = 8;
  hsai_BlockA1.SlotInit.SlotActive = 0x0000FFFF;
  if (HAL_SAI_Init(&hsai_BlockA1) != HAL_OK)
  {
    Error_Handler();
  }
  hsai_BlockB1.Instance = SAI1_Block_B;
  hsai_BlockB1.Init.Protocol = SAI_FREE_PROTOCOL;
  hsai_BlockB1.Init.AudioMode = SAI_MODESLAVE_TX;
  hsai_BlockB1.Init.DataSize = SAI_DATASIZE_24;
  hsai_BlockB1.Init.FirstBit = SAI_FIRSTBIT_MSB;
  hsai_BlockB1.Init.ClockStrobing = SAI_CLOCKSTROBING_FALLINGEDGE;
  hsai_BlockB1.Init.Synchro = SAI_SYNCHRONOUS;
  hsai_BlockB1.Init.OutputDrive = SAI_OUTPUTDRIVE_ENABLE;
  hsai_BlockB1.Init.FIFOThreshold = SAI_FIFOTHRESHOLD_EMPTY;
  hsai_BlockB1.Init.SynchroExt = SAI_SYNCEXT_DISABLE;
  hsai_BlockB1.Init.MonoStereoMode = SAI_STEREOMODE;
  hsai_BlockB1.Init.CompandingMode = SAI_NOCOMPANDING;
  hsai_BlockB1.Init.TriState = SAI_OUTPUT_NOTRELEASED;
  hsai_BlockB1.Init.PdmInit.Activation = DISABLE;
  hsai_BlockB1.Init.PdmInit.MicPairsNbr = 1;
  hsai_BlockB1.Init.PdmInit.ClockEnable = SAI_PDM_CLOCK1_ENABLE;
  hsai_BlockB1.FrameInit.FrameLength = 256;
  hsai_BlockB1.FrameInit.ActiveFrameLength = 128;
  hsai_BlockB1.FrameInit.FSDefinition = SAI_FS_CHANNEL_IDENTIFICATION;
  hsai_BlockB1.FrameInit.FSPolarity = SAI_FS_ACTIVE_HIGH;
  hsai_BlockB1.FrameInit.FSOffset = SAI_FS_BEFOREFIRSTBIT;
  hsai_BlockB1.SlotInit.FirstBitOffset = 0;
  hsai_BlockB1.SlotInit.SlotSize = SAI_SLOTSIZE_32B;
  hsai_BlockB1.SlotInit.SlotNumber = 8;
  hsai_BlockB1.SlotInit.SlotActive = 0x0000FFFF;
  if (HAL_SAI_Init(&hsai_BlockB1) != HAL_OK)
  {
    Error_Handler();
  }

}

static void MX_SPI2_Init(void)
{

  /* SPI2 parameter configuration*/
  hspi2.Instance = SPI2;
  hspi2.Init.Mode = SPI_MODE_MASTER;
  hspi2.Init.Direction = SPI_DIRECTION_2LINES;
  hspi2.Init.DataSize = SPI_DATASIZE_8BIT;
  hspi2.Init.CLKPolarity = SPI_POLARITY_HIGH;
  hspi2.Init.CLKPhase = SPI_PHASE_2EDGE;
  hspi2.Init.NSS = SPI_NSS_SOFT;
  hspi2.Init.BaudRatePrescaler = SPI_BAUDRATEPRESCALER_256;
  hspi2.Init.FirstBit = SPI_FIRSTBIT_MSB;
  hspi2.Init.TIMode = SPI_TIMODE_DISABLE;
  hspi2.Init.CRCCalculation = SPI_CRCCALCULATION_DISABLE;
  hspi2.Init.CRCPolynomial = 0x0;
  hspi2.Init.NSSPMode = SPI_NSS_PULSE_DISABLE;
  hspi2.Init.NSSPolarity = SPI_NSS_POLARITY_LOW;
  hspi2.Init.FifoThreshold = SPI_FIFO_THRESHOLD_01DATA;
  hspi2.Init.TxCRCInitializationPattern = SPI_CRC_INITIALIZATION_ALL_ZERO_PATTERN;
  hspi2.Init.RxCRCInitializationPattern = SPI_CRC_INITIALIZATION_ALL_ZERO_PATTERN;
  hspi2.Init.MasterSSIdleness = SPI_MASTER_SS_IDLENESS_00CYCLE;
  hspi2.Init.MasterInterDataIdleness = SPI_MASTER_INTERDATA_IDLENESS_00CYCLE;
  hspi2.Init.MasterReceiverAutoSusp = SPI_MASTER_RX_AUTOSUSP_DISABLE;
  hspi2.Init.MasterKeepIOState = SPI_MASTER_KEEP_IO_STATE_DISABLE;
  hspi2.Init.IOSwap = SPI_IO_SWAP_DISABLE;
  if (HAL_SPI_Init(&hspi2) != HAL_OK)
  {
    Error_Handler();
  }

}

static void MX_SPI3_Init(void)
{

  /* SPI3 parameter configuration*/
  hspi3.Instance = SPI3;
  hspi3.Init.Mode = SPI_MODE_MASTER;
  hspi3.Init.Direction = SPI_DIRECTION_2LINES_TXONLY;
  hspi3.Init.DataSize = SPI_DATASIZE_8BIT;
  hspi3.Init.CLKPolarity = SPI_POLARITY_LOW;
  hspi3.Init.CLKPhase = SPI_PHASE_1EDGE;
  hspi3.Init.NSS = SPI_NSS_SOFT;
  hspi3.Init.BaudRatePrescaler = SPI_BAUDRATEPRESCALER_16;
  hspi3.Init.FirstBit = SPI_FIRSTBIT_MSB;
  hspi3.Init.TIMode = SPI_TIMODE_DISABLE;
  hspi3.Init.CRCCalculation = SPI_CRCCALCULATION_DISABLE;
  hspi3.Init.CRCPolynomial = 0x0;
  hspi3.Init.NSSPMode = SPI_NSS_PULSE_DISABLE;
  hspi3.Init.NSSPolarity = SPI_NSS_POLARITY_LOW;
  hspi3.Init.FifoThreshold = SPI_FIFO_THRESHOLD_01DATA;
  hspi3.Init.TxCRCInitializationPattern = SPI_CRC_INITIALIZATION_ALL_ZERO_PATTERN;
  hspi3.Init.RxCRCInitializationPattern = SPI_CRC_INITIALIZATION_ALL_ZERO_PATTERN;
  hspi3.Init.MasterSSIdleness = SPI_MASTER_SS_IDLENESS_00CYCLE;
  hspi3.Init.MasterInterDataIdleness = SPI_MASTER_INTERDATA_IDLENESS_00CYCLE;
  hspi3.Init.MasterReceiverAutoSusp = SPI_MASTER_RX_AUTOSUSP_DISABLE;
  hspi3.Init.MasterKeepIOState = SPI_MASTER_KEEP_IO_STATE_DISABLE;
  hspi3.Init.IOSwap = SPI_IO_SWAP_DISABLE;
  if (HAL_SPI_Init(&hspi3) != HAL_OK)
  {
    Error_Handler();
  }

}

static void MX_TIM2_Init(void)
{

  TIM_Encoder_InitTypeDef sConfig = {0};
  TIM_MasterConfigTypeDef sMasterConfig = {0};

  htim2.Instance = TIM2;
  htim2.Init.Prescaler = 0;
  htim2.Init.CounterMode = TIM_COUNTERMODE_UP;
  htim2.Init.Period = 4294967295;
  htim2.Init.ClockDivision = TIM_CLOCKDIVISION_DIV1;
  htim2.Init.AutoReloadPreload = TIM_AUTORELOAD_PRELOAD_DISABLE;
  sConfig.EncoderMode = TIM_ENCODERMODE_TI1;
  sConfig.IC1Polarity = TIM_ICPOLARITY_RISING;
  sConfig.IC1Selection = TIM_ICSELECTION_DIRECTTI;
  sConfig.IC1Prescaler = TIM_ICPSC_DIV1;
  sConfig.IC1Filter = 0;
  sConfig.IC2Polarity = TIM_ICPOLARITY_RISING;
  sConfig.IC2Selection = TIM_ICSELECTION_DIRECTTI;
  sConfig.IC2Prescaler = TIM_ICPSC_DIV1;
  sConfig.IC2Filter = 0;
  if (HAL_TIM_Encoder_Init(&htim2, &sConfig) != HAL_OK)
  {
    Error_Handler();
  }
  sMasterConfig.MasterOutputTrigger = TIM_TRGO_RESET;
  sMasterConfig.MasterSlaveMode = TIM_MASTERSLAVEMODE_DISABLE;
  if (HAL_TIMEx_MasterConfigSynchronization(&htim2, &sMasterConfig) != HAL_OK)
  {
    Error_Handler();
  }

}

static void MX_TIM3_Init(void)
{

  TIM_Encoder_InitTypeDef sConfig = {0};
  TIM_MasterConfigTypeDef sMasterConfig = {0};

  htim3.Instance = TIM3;
  htim3.Init.Prescaler = 0;
  htim3.Init.CounterMode = TIM_COUNTERMODE_UP;
  htim3.Init.Period = 65535;
  htim3.Init.ClockDivision = TIM_CLOCKDIVISION_DIV1;
  htim3.Init.AutoReloadPreload = TIM_AUTORELOAD_PRELOAD_DISABLE;
  sConfig.EncoderMode = TIM_ENCODERMODE_TI1;
  sConfig.IC1Polarity = TIM_ICPOLARITY_RISING;
  sConfig.IC1Selection = TIM_ICSELECTION_DIRECTTI;
  sConfig.IC1Prescaler = TIM_ICPSC_DIV1;
  sConfig.IC1Filter = 0;
  sConfig.IC2Polarity = TIM_ICPOLARITY_RISING;
  sConfig.IC2Selection = TIM_ICSELECTION_DIRECTTI;
  sConfig.IC2Prescaler = TIM_ICPSC_DIV1;
  sConfig.IC2Filter = 0;
  if (HAL_TIM_Encoder_Init(&htim3, &sConfig) != HAL_OK)
  {
    Error_Handler();
  }
  sMasterConfig.MasterOutputTrigger = TIM_TRGO_RESET;
  sMasterConfig.MasterSlaveMode = TIM_MASTERSLAVEMODE_DISABLE;
  if (HAL_TIMEx_MasterConfigSynchronization(&htim3, &sMasterConfig) != HAL_OK)
  {
    Error_Handler();
  }

}

static void MX_TIM4_Init(void)
{

  TIM_Encoder_InitTypeDef sConfig = {0};
  TIM_MasterConfigTypeDef sMasterConfig = {0};

  htim4.Instance = TIM4;
  htim4.Init.Prescaler = 0;
  htim4.Init.CounterMode = TIM_COUNTERMODE_UP;
  htim4.Init.Period = 65535;
  htim4.Init.ClockDivision = TIM_CLOCKDIVISION_DIV1;
  htim4.Init.AutoReloadPreload = TIM_AUTORELOAD_PRELOAD_DISABLE;
  sConfig.EncoderMode = TIM_ENCODERMODE_TI12;
  sConfig.IC1Polarity = TIM_ICPOLARITY_RISING;
  sConfig.IC1Selection = TIM_ICSELECTION_DIRECTTI;
  sConfig.IC1Prescaler = TIM_ICPSC_DIV1;
  sConfig.IC1Filter = 4;
  sConfig.IC2Polarity = TIM_ICPOLARITY_RISING;
  sConfig.IC2Selection = TIM_ICSELECTION_DIRECTTI;
  sConfig.IC2Prescaler = TIM_ICPSC_DIV1;
  sConfig.IC2Filter = 4;
  if (HAL_TIM_Encoder_Init(&htim4, &sConfig) != HAL_OK)
  {
    Error_Handler();
  }
  sMasterConfig.MasterOutputTrigger = TIM_TRGO_RESET;
  sMasterConfig.MasterSlaveMode = TIM_MASTERSLAVEMODE_DISABLE;
  if (HAL_TIMEx_MasterConfigSynchronization(&htim4, &sMasterConfig) != HAL_OK)
  {
    Error_Handler();
  }

}

static void MX_UART5_Init(void)
{

  huart5.Instance = UART5;
  huart5.Init.BaudRate = 115200;
  huart5.Init.WordLength = UART_WORDLENGTH_8B;
  huart5.Init.StopBits = UART_STOPBITS_1;
  huart5.Init.Parity = UART_PARITY_NONE;
  huart5.Init.Mode = UART_MODE_TX_RX;
  huart5.Init.HwFlowCtl = UART_HWCONTROL_NONE;
  huart5.Init.OverSampling = UART_OVERSAMPLING_16;
  huart5.Init.OneBitSampling = UART_ONE_BIT_SAMPLE_DISABLE;
  huart5.Init.ClockPrescaler = UART_PRESCALER_DIV1;
  huart5.AdvancedInit.AdvFeatureInit = UART_ADVFEATURE_NO_INIT;
  if (HAL_UART_Init(&huart5) != HAL_OK)
  {
    Error_Handler();
  }
  if (HAL_UARTEx_SetTxFifoThreshold(&huart5, UART_TXFIFO_THRESHOLD_1_8) != HAL_OK)
  {
    Error_Handler();
  }
  if (HAL_UARTEx_SetRxFifoThreshold(&huart5, UART_RXFIFO_THRESHOLD_1_8) != HAL_OK)
  {
    Error_Handler();
  }
  if (HAL_UARTEx_DisableFifoMode(&huart5) != HAL_OK)
  {
    Error_Handler();
  }

}

static void MX_UART7_Init(void)
{

  huart7.Instance = UART7;
  huart7.Init.BaudRate = 115200;
  huart7.Init.WordLength = UART_WORDLENGTH_8B;
  huart7.Init.StopBits = UART_STOPBITS_1;
  huart7.Init.Parity = UART_PARITY_NONE;
  huart7.Init.Mode = UART_MODE_TX_RX;
  huart7.Init.HwFlowCtl = UART_HWCONTROL_NONE;
  huart7.Init.OverSampling = UART_OVERSAMPLING_16;
  huart7.Init.OneBitSampling = UART_ONE_BIT_SAMPLE_DISABLE;
  huart7.Init.ClockPrescaler = UART_PRESCALER_DIV1;
  huart7.AdvancedInit.AdvFeatureInit = UART_ADVFEATURE_NO_INIT;
  if (HAL_UART_Init(&huart7) != HAL_OK)
  {
    Error_Handler();
  }
  if (HAL_UARTEx_SetTxFifoThreshold(&huart7, UART_TXFIFO_THRESHOLD_1_8) != HAL_OK)
  {
    Error_Handler();
  }
  if (HAL_UARTEx_SetRxFifoThreshold(&huart7, UART_RXFIFO_THRESHOLD_1_8) != HAL_OK)
  {
    Error_Handler();
  }
  if (HAL_UARTEx_DisableFifoMode(&huart7) != HAL_OK)
  {
    Error_Handler();
  }

}

static void MX_DMA_Init(void)
{

  /* DMA controller clock enable */
  __HAL_RCC_DMA1_CLK_ENABLE();

  /* DMA interrupt init */
  /* DMA1_Stream0_IRQn interrupt configuration */
  HAL_NVIC_SetPriority(DMA1_Stream0_IRQn, 5, 0);
  HAL_NVIC_EnableIRQ(DMA1_Stream0_IRQn);
  /* DMA1_Stream1_IRQn interrupt configuration */
  HAL_NVIC_SetPriority(DMA1_Stream1_IRQn, 5, 0);
  HAL_NVIC_EnableIRQ(DMA1_Stream1_IRQn);
  /* DMA1_Stream2_IRQn interrupt configuration */
  HAL_NVIC_SetPriority(DMA1_Stream2_IRQn, 5, 0);
  HAL_NVIC_EnableIRQ(DMA1_Stream2_IRQn);
  /* DMA1_Stream3_IRQn interrupt configuration */
  HAL_NVIC_SetPriority(DMA1_Stream3_IRQn, 5, 0);
  HAL_NVIC_EnableIRQ(DMA1_Stream3_IRQn);

}

/* FMC initialization function */
static void MX_FMC_Init(void)
{

  FMC_SDRAM_TimingTypeDef SdramTiming = {0};

  /** Perform the SDRAM1 memory initialization sequence
  */
  hsdram1.Instance = FMC_SDRAM_DEVICE;
  /* hsdram1.Init */
  hsdram1.Init.SDBank = FMC_SDRAM_BANK1;
  hsdram1.Init.ColumnBitsNumber = FMC_SDRAM_COLUMN_BITS_NUM_8;
  hsdram1.Init.RowBitsNumber = FMC_SDRAM_ROW_BITS_NUM_13;
  hsdram1.Init.MemoryDataWidth = FMC_SDRAM_MEM_BUS_WIDTH_32;
  hsdram1.Init.InternalBankNumber = FMC_SDRAM_INTERN_BANKS_NUM_4;
  hsdram1.Init.CASLatency = FMC_SDRAM_CAS_LATENCY_1;
  hsdram1.Init.WriteProtection = FMC_SDRAM_WRITE_PROTECTION_DISABLE;
  hsdram1.Init.SDClockPeriod = FMC_SDRAM_CLOCK_DISABLE;
  hsdram1.Init.ReadBurst = FMC_SDRAM_RBURST_DISABLE;
  hsdram1.Init.ReadPipeDelay = FMC_SDRAM_RPIPE_DELAY_0;
  /* SdramTiming */
  SdramTiming.LoadToActiveDelay = 16;
  SdramTiming.ExitSelfRefreshDelay = 16;
  SdramTiming.SelfRefreshTime = 16;
  SdramTiming.RowCycleDelay = 16;
  SdramTiming.WriteRecoveryTime = 16;
  SdramTiming.RPDelay = 16;
  SdramTiming.RCDDelay = 16;

  if (HAL_SDRAM_Init(&hsdram1, &SdramTiming) != HAL_OK)
  {
    Error_Handler( );
  }

}

static void MX_GPIO_Init(void)
{
  GPIO_InitTypeDef GPIO_InitStruct = {0};

  /* GPIO Ports Clock Enable */
  __HAL_RCC_GPIOE_CLK_ENABLE();
  __HAL_RCC_GPIOB_CLK_ENABLE();
  __HAL_RCC_GPIOG_CLK_ENABLE();
  __HAL_RCC_GPIOD_CLK_ENABLE();
  __HAL_RCC_GPIOC_CLK_ENABLE();
  __HAL_RCC_GPIOA_CLK_ENABLE();
  __HAL_RCC_GPIOI_CLK_ENABLE();
  __HAL_RCC_GPIOH_CLK_ENABLE();
  __HAL_RCC_GPIOF_CLK_ENABLE();

  /*Configure GPIO pin Output Level */
  HAL_GPIO_WritePin(GPIOG, OLED_CS_Pin|ADC_RST_Pin, GPIO_PIN_RESET);

  /*Configure GPIO pin Output Level */
  HAL_GPIO_WritePin(OLED_DC_GPIO_Port, OLED_DC_Pin, GPIO_PIN_RESET);

  /*Configure GPIO pin Output Level */
  HAL_GPIO_WritePin(GPIOI, GPIO_PIN_11, GPIO_PIN_RESET);

  /*Configure GPIO pin Output Level */
  HAL_GPIO_WritePin(GPIOH, GPIO_PIN_4, GPIO_PIN_RESET);

  /*Configure GPIO pin Output Level */
  HAL_GPIO_WritePin(GPIOA, OLED_RST_Pin|GPIO_PIN_3|GPIO_PIN_7, GPIO_PIN_RESET);

  /*Configure GPIO pin Output Level */
  HAL_GPIO_WritePin(ADC_SPI_NCS_GPIO_Port, ADC_SPI_NCS_Pin, GPIO_PIN_RESET);

  /*Configure GPIO pins : PB8 PB4 PB9 PB2
                           PB12 PB13 PB14 PB15 */
  GPIO_InitStruct.Pin = GPIO_PIN_8|GPIO_PIN_4|GPIO_PIN_9|GPIO_PIN_2
                          |GPIO_PIN_12|GPIO_PIN_13|GPIO_PIN_14|GPIO_PIN_15;
  GPIO_InitStruct.Mode = GPIO_MODE_ANALOG;
  GPIO_InitStruct.Pull = GPIO_NOPULL;
  HAL_GPIO_Init(GPIOB, &GPIO_InitStruct);

  /*Configure GPIO pin : OLED_CS_Pin */
  GPIO_InitStruct.Pin = OLED_CS_Pin;
  GPIO_InitStruct.Mode = GPIO_MODE_OUTPUT_PP;
  GPIO_InitStruct.Pull = GPIO_NOPULL;
  GPIO_InitStruct.Speed = GPIO_SPEED_FREQ_MEDIUM;
  HAL_GPIO_Init(OLED_CS_GPIO_Port, &GPIO_InitStruct);

  /*Configure GPIO pins : PG13 PG9 */
  GPIO_InitStruct.Pin = GPIO_PIN_13|GPIO_PIN_9;
  GPIO_InitStruct.Mode = GPIO_MODE_ANALOG;
  GPIO_InitStruct.Pull = GPIO_NOPULL;
  HAL_GPIO_Init(GPIOG, &GPIO_InitStruct);

  /*Configure GPIO pins : PD7 PD6 PD5 PD4
                           PD3 PD11 */
  GPIO_InitStruct.Pin = GPIO_PIN_7|GPIO_PIN_6|GPIO_PIN_5|GPIO_PIN_4
                          |GPIO_PIN_3|GPIO_PIN_11;
  GPIO_InitStruct.Mode = GPIO_MODE_ANALOG;
  GPIO_InitStruct.Pull = GPIO_NOPULL;
  HAL_GPIO_Init(GPIOD, &GPIO_InitStruct);

  /*Configure GPIO pin : PB7 */
  GPIO_InitStruct.Pin = GPIO_PIN_7;
  GPIO_InitStruct.Mode = GPIO_MODE_AF_OD;
  GPIO_InitStruct.Pull = GPIO_NOPULL;
  GPIO_InitStruct.Speed = GPIO_SPEED_FREQ_LOW;
  GPIO_InitStruct.Alternate = GPIO_AF4_I2C1;
  HAL_GPIO_Init(GPIOB, &GPIO_InitStruct);

  /*Configure GPIO pin : PG10 */
  GPIO_InitStruct.Pin = GPIO_PIN_10;
  GPIO_InitStruct.Mode = GPIO_MODE_INPUT;
  GPIO_InitStruct.Pull = GPIO_NOPULL;
  HAL_GPIO_Init(GPIOG, &GPIO_InitStruct);

  /*Configure GPIO pin : OLED_DC_Pin */
  GPIO_InitStruct.Pin = OLED_DC_Pin;
  GPIO_InitStruct.Mode = GPIO_MODE_OUTPUT_PP;
  GPIO_InitStruct.Pull = GPIO_NOPULL;
  GPIO_InitStruct.Speed = GPIO_SPEED_FREQ_MEDIUM;
  HAL_GPIO_Init(OLED_DC_GPIO_Port, &GPIO_InitStruct);

  /*Configure GPIO pins : EXTI13_Pin EXTI14_Pin PC9 PC8 */
  GPIO_InitStruct.Pin = EXTI13_Pin|EXTI14_Pin|GPIO_PIN_9|GPIO_PIN_8;
  GPIO_InitStruct.Mode = GPIO_MODE_IT_RISING;
  GPIO_InitStruct.Pull = GPIO_NOPULL;
  HAL_GPIO_Init(GPIOC, &GPIO_InitStruct);

  /*Configure GPIO pin : PI8 */
  GPIO_InitStruct.Pin = GPIO_PIN_8;
  GPIO_InitStruct.Mode = GPIO_MODE_ANALOG;
  GPIO_InitStruct.Pull = GPIO_NOPULL;
  HAL_GPIO_Init(GPIOI, &GPIO_InitStruct);

  /*Configure GPIO pin : PD2 */
  GPIO_InitStruct.Pin = GPIO_PIN_2;
  GPIO_InitStruct.Mode = GPIO_MODE_IT_RISING;
  GPIO_InitStruct.Pull = GPIO_NOPULL;
  HAL_GPIO_Init(GPIOD, &GPIO_InitStruct);

  /*Configure GPIO pins : PA10 PA5 */
  GPIO_InitStruct.Pin = GPIO_PIN_10|GPIO_PIN_5;
  GPIO_InitStruct.Mode = GPIO_MODE_ANALOG;
  GPIO_InitStruct.Pull = GPIO_NOPULL;
  HAL_GPIO_Init(GPIOA, &GPIO_InitStruct);

  /*Configure GPIO pin : PI11 */
  GPIO_InitStruct.Pin = GPIO_PIN_11;
  GPIO_InitStruct.Mode = GPIO_MODE_OUTPUT_PP;
  GPIO_InitStruct.Pull = GPIO_NOPULL;
  GPIO_InitStruct.Speed = GPIO_SPEED_FREQ_LOW;
  HAL_GPIO_Init(GPIOI, &GPIO_InitStruct);

  /*Configure GPIO pin : PC15 */
  GPIO_InitStruct.Pin = GPIO_PIN_15;
  GPIO_InitStruct.Mode = GPIO_MODE_INPUT;
  GPIO_InitStruct.Pull = GPIO_NOPULL;
  HAL_GPIO_Init(GPIOC, &GPIO_InitStruct);

  /*Configure GPIO pin : PH4 */
  GPIO_InitStruct.Pin = GPIO_PIN_4;
  GPIO_InitStruct.Mode = GPIO_MODE_OUTPUT_PP;
  GPIO_InitStruct.Pull = GPIO_NOPULL;
  GPIO_InitStruct.Speed = GPIO_SPEED_FREQ_LOW;
  HAL_GPIO_Init(GPIOH, &GPIO_InitStruct);

  /*Configure GPIO pin : ADC_RST_Pin */
  GPIO_InitStruct.Pin = ADC_RST_Pin;
  GPIO_InitStruct.Mode = GPIO_MODE_OUTPUT_PP;
  GPIO_InitStruct.Pull = GPIO_NOPULL;
  GPIO_InitStruct.Speed = GPIO_SPEED_FREQ_LOW;
  HAL_GPIO_Init(ADC_RST_GPIO_Port, &GPIO_InitStruct);

  /*Configure GPIO pins : PH6 PH7 */
  GPIO_InitStruct.Pin = GPIO_PIN_6|GPIO_PIN_7;
  GPIO_InitStruct.Mode = GPIO_MODE_ANALOG;
  GPIO_InitStruct.Pull = GPIO_NOPULL;
  HAL_GPIO_Init(GPIOH, &GPIO_InitStruct);

  /*Configure GPIO pins : PA0 PA6 */
  GPIO_InitStruct.Pin = GPIO_PIN_0|GPIO_PIN_6;
  GPIO_InitStruct.Mode = GPIO_MODE_INPUT;
  GPIO_InitStruct.Pull = GPIO_NOPULL;
  HAL_GPIO_Init(GPIOA, &GPIO_InitStruct);

  /*Configure GPIO pin : OLED_RST_Pin */
  GPIO_InitStruct.Pin = OLED_RST_Pin;
  GPIO_InitStruct.Mode = GPIO_MODE_OUTPUT_PP;
  GPIO_InitStruct.Pull = GPIO_NOPULL;
  GPIO_InitStruct.Speed = GPIO_SPEED_FREQ_MEDIUM;
  HAL_GPIO_Init(OLED_RST_GPIO_Port, &GPIO_InitStruct);

  /*Configure GPIO pin : PC4 */
  GPIO_InitStruct.Pin = GPIO_PIN_4;
  GPIO_InitStruct.Mode = GPIO_MODE_ANALOG;
  GPIO_InitStruct.Pull = GPIO_NOPULL;
  HAL_GPIO_Init(GPIOC, &GPIO_InitStruct);

  /*Configure GPIO pins : PA3 PA7 */
  GPIO_InitStruct.Pin = GPIO_PIN_3|GPIO_PIN_7;
  GPIO_InitStruct.Mode = GPIO_MODE_OUTPUT_PP;
  GPIO_InitStruct.Pull = GPIO_NOPULL;
  GPIO_InitStruct.Speed = GPIO_SPEED_FREQ_LOW;
  HAL_GPIO_Init(GPIOA, &GPIO_InitStruct);

  /*Configure GPIO pin : ADC_SPI_NCS_Pin */
  GPIO_InitStruct.Pin = ADC_SPI_NCS_Pin;
  GPIO_InitStruct.Mode = GPIO_MODE_OUTPUT_PP;
  GPIO_InitStruct.Pull = GPIO_NOPULL;
  GPIO_InitStruct.Speed = GPIO_SPEED_FREQ_LOW;
  HAL_GPIO_Init(ADC_SPI_NCS_GPIO_Port, &GPIO_InitStruct);

  /* EXTI interrupt init*/
  HAL_NVIC_SetPriority(EXTI2_IRQn, 5, 0);
  HAL_NVIC_EnableIRQ(EXTI2_IRQn);

  HAL_NVIC_SetPriority(EXTI9_5_IRQn, 5, 0);
  HAL_NVIC_EnableIRQ(EXTI9_5_IRQn);

  HAL_NVIC_SetPriority(EXTI15_10_IRQn, 5, 0);
  HAL_NVIC_EnableIRQ(EXTI15_10_IRQn);

}

void StartDefaultTask(void const * argument)
{
  /* init code for USB_DEVICE */
  MX_USB_DEVICE_Init();
  /* USER CODE BEGIN 5 */

  setup();

  /* Infinite loop */
  for(;;)
  {
    loop();
  }
  /* USER CODE END 5 */
}

void Error_Handler(void)
{
  /* USER CODE BEGIN Error_Handler_Debug */
#ifdef DEBUG
  __asm__("BKPT");
#else
  NVIC_SystemReset();
#endif
  /* USER CODE END Error_Handler_Debug */
}

#ifdef  USE_FULL_ASSERT
/**
  * @brief  Reports the name of the source file and the source line number
  *         where the assert_param error has occurred.
  * @param  file: pointer to the source file name
  * @param  line: assert_param error line source number
  * @retval None
  */
void assert_failed(uint8_t *file, uint32_t line)
{
  /* USER CODE BEGIN 6 */
#ifdef DEBUG
  __asm__("BKPT");
#else
  NVIC_SystemReset();
#endif
  /* USER CODE END 6 */
}
#endif /* USE_FULL_ASSERT */

/************************ (C) COPYRIGHT STMicroelectronics *****END OF FILE****/

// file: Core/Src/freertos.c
/* USER CODE BEGIN Header */
/**
  ******************************************************************************
  * File Name          : freertos.c
  * Description        : Code for freertos applications
  ******************************************************************************
  * @attention
  *
  * <h2><center>&copy; Copyright (c) 2021 STMicroelectronics.
  * All rights reserved.</center></h2>
  *
  * This software component is licensed by ST under Ultimate Liberty license
  * SLA0044, the "License"; You may not use this file except in compliance with
  * the License. You may obtain a copy of the License at:
  *                             www.st.com/SLA0044
  *
  ******************************************************************************
  */
/* USER CODE END Header */

#include "FreeRTOS.h"
#include "task.h"
#include "main.h"

/* GetIdleTaskMemory prototype (linked to static allocation support) */
void vApplicationGetIdleTaskMemory( StaticTask_t **ppxIdleTaskTCBBuffer, StackType_t **ppxIdleTaskStackBuffer, uint32_t *pulIdleTaskStackSize );

/* Hook prototypes */
void vApplicationIdleHook(void);
void vApplicationTickHook(void);
void vApplicationMallocFailedHook(void);

/* USER CODE BEGIN 2 */
__weak void vApplicationIdleHook( void )
{
   /* vApplicationIdleHook() will only be called if configUSE_IDLE_HOOK is set
   to 1 in FreeRTOSConfig.h. It will be called on each iteration of the idle
   task. It is essential that code added to this hook function never attempts
   to block in any way (for example, call xQueueReceive() with a block time
   specified, or call vTaskDelay()). If the application makes use of the
   vTaskDelete() API function (as this demo application does) then it is also
   important that vApplicationIdleHook() is permitted to return to its calling
   function, because it is the responsibility of the idle task to clean up
   memory allocated by the kernel to any task that has since been deleted. */
}
/* USER CODE END 2 */

/* USER CODE BEGIN 3 */
__weak void vApplicationTickHook( void )
{
   /* This function will be called by each tick interrupt if
   configUSE_TICK_HOOK is set to 1 in FreeRTOSConfig.h. User code can be
   added here, but the tick hook is called from an interrupt context, so
   code must not attempt to block, and only the interrupt safe FreeRTOS API
   functions can be used (those that end in FromISR()). */
}
/* USER CODE END 3 */

/* USER CODE BEGIN 5 */
__weak void vApplicationMallocFailedHook(void)
{
   /* vApplicationMallocFailedHook() will only be called if
   configUSE_MALLOC_FAILED_HOOK is set to 1 in FreeRTOSConfig.h. It is a hook
   function that will get called if a call to pvPortMalloc() fails.
   pvPortMalloc() is called internally by the kernel whenever a task, queue,
   timer or semaphore is created. It is also called by various parts of the
   demo application. If heap_1.c or heap_2.c are used, then the size of the
   heap available to pvPortMalloc() is defined by configTOTAL_HEAP_SIZE in
   FreeRTOSConfig.h, and the xPortGetFreeHeapSize() API function can be used
   to query the size of free heap space that remains (although it does not
   provide information on how the remaining heap might be fragmented). */
}
/* USER CODE END 5 */

/* USER CODE BEGIN GET_IDLE_TASK_MEMORY */
static StaticTask_t xIdleTaskTCBBuffer;
static StackType_t xIdleStack[configMINIMAL_STACK_SIZE];

void vApplicationGetIdleTaskMemory( StaticTask_t **ppxIdleTaskTCBBuffer, StackType_t **ppxIdleTaskStackBuffer, uint32_t *pulIdleTaskStackSize )
{
  *ppxIdleTaskTCBBuffer = &xIdleTaskTCBBuffer;
  *ppxIdleTaskStackBuffer = &xIdleStack[0];
  *pulIdleTaskStackSize = configMINIMAL_STACK_SIZE;
  /* place for user code */
}
/* USER CODE END GET_IDLE_TASK_MEMORY */

/************************ (C) COPYRIGHT STMicroelectronics *****END OF FILE****/
